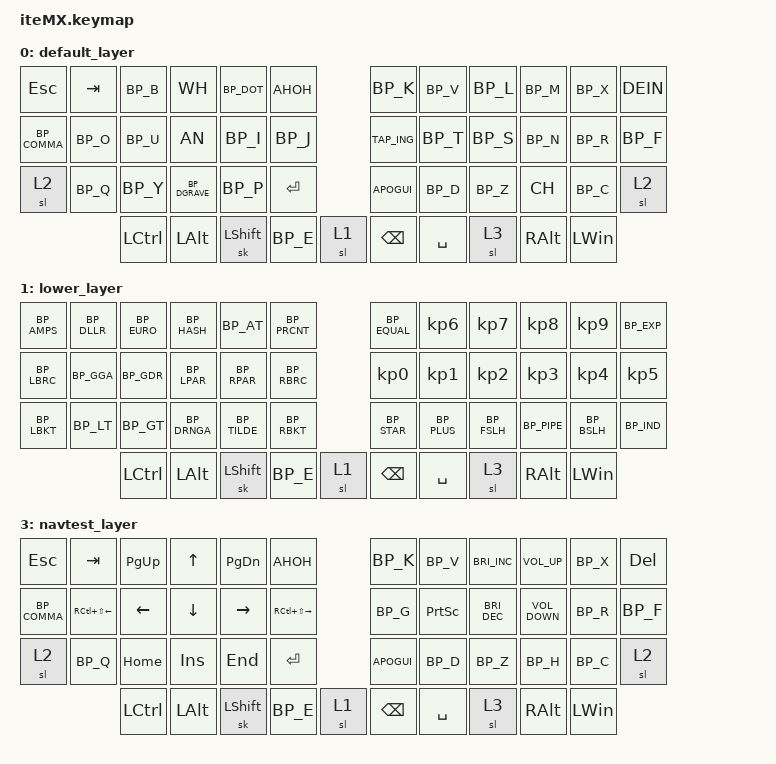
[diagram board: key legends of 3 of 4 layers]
#include <behaviors.dtsi>
#include "keys_bepo.h"
#include <dt-bindings/zmk/bt.h>
#include "mouse.dtsi"
#include <dt-bindings/zmk/outputs.h>
#include <dt-bindings/zmk/keys.h>

//shift circonflexe pour deux point sur le I1

#define default 0
#define lower 1
#define nav 2
#define navtest 3

&sk {
    release-after-ms = <1000>;
    quick-release;
    /delete-property/ ignore-modifiers;
};

/ {
    macros {
        MACRO_WH: WH {
            label = "WH";
            compatible = "zmk,behavior-macro";
            #binding-cells = <0>;
            bindings
                = <&macro_tap &kp BP_W &kp BP_H>
                ;
        };
        MACRO_MAJ_WH: MAJ_WH {
            label = "MAJ_WH";
            compatible = "zmk,behavior-macro";
            #binding-cells = <0>;
            bindings
            = <&macro_tap &kp LS(BP_W) &kp BP_H>
            ;
        };
        MACRO_ING: ING {
            label = "ING";
            compatible = "zmk,behavior-macro";
            #binding-cells = <0>;
            bindings
                = <&macro_tap &kp BP_I &kp BP_N &kp BP_G>
                ;
        };
        MACRO_CH: CH {
            label = "CH";
            compatible = "zmk,behavior-macro";
            #binding-cells = <0>;
            bindings
                = <&macro_tap &kp BP_C &kp BP_H>
                ;
        };
        MACRO_MAJ_CH: MAJ_CH {
            label = "MAJ_CH";
            compatible = "zmk,behavior-macro";
            #binding-cells = <0>;
            bindings
            = <&macro_tap &kp LS(BP_C) &kp BP_H>
            ;
        };
        MACRO_AN: AN {
            label = "AN";
            compatible = "zmk,behavior-macro";
            #binding-cells = <0>;
            bindings
                = <&macro_tap &kp BP_A &kp BP_N>
                ;
        };
        MACRO_MAJ_AN: MAJ_AN {
            label = "MAJ_AN";
            compatible = "zmk,behavior-macro";
            #binding-cells = <0>;
            bindings
            = <&macro_tap &kp LS(BP_A) &kp BP_N>
            ;
        };
    };
};

/ {
    behaviors {
        TAP_WH: tap_dance_0 {
            compatible = "zmk,behavior-tap-dance";
            label = "TAP_DANCE_0";
            #binding-cells = <0>;
            tapping-term-ms = <150>;
            bindings = <&kp BP_W>, <&MACRO_WH>;
        };
        TAP_MAJ_WH: tap_dance_1 {
            compatible = "zmk,behavior-tap-dance";
            label = "TAP_DANCE_1";
            #binding-cells = <0>;
            tapping-term-ms = <150>;
            bindings = <&kp BP_W>, <&MACRO_MAJ_WH>;
        };
        TAP_ING: tap_dance_2 {
            compatible = "zmk,behavior-tap-dance";
            label = "TAP_DANCE_2";
            #binding-cells = <0>;
            tapping-term-ms = <150>;
            bindings = <&kp BP_G>, <&MACRO_ING>;
        };
        TAP_CH: tap_dance_3 {
            compatible = "zmk,behavior-tap-dance";
            label = "TAP_DANCE_3";
            #binding-cells = <0>;
            tapping-term-ms = <150>;
            bindings = <&kp BP_H>, <&MACRO_CH>;
        };
        TAP_MAJ_CH: tap_dance_4 {
            compatible = "zmk,behavior-tap-dance";
            label = "TAP_DANCE_4";
            #binding-cells = <0>;
            tapping-term-ms = <150>;
            bindings = <&kp BP_H>, <&MACRO_MAJ_CH>;
        };
        TAP_AN: tap_dance_5 {
            compatible = "zmk,behavior-tap-dance";
            label = "TAP_DANCE_5";
            #binding-cells = <0>;
            tapping-term-ms = <150>;
            bindings = <&kp BP_A>, <&MACRO_AN>;
        };
        TAP_MAJ_AN: tap_dance_6 {
            compatible = "zmk,behavior-tap-dance";
            label = "TAP_DANCE_6";
            #binding-cells = <0>;
            tapping-term-ms = <150>;
            bindings = <&kp BP_A>, <&MACRO_MAJ_AN>;
        };
    };
};

/ {
    behaviors {
        AHOH: exclamation_question {
            compatible = "zmk,behavior-mod-morph";
            label = "EXCLAMATION_QUESTION";
            #binding-cells = <0>;
            bindings = <&kp BP_QMARK>, <&kp BP_EXCL>;
            mods = <(MOD_LSFT|MOD_RSFT)>;
        };
        APOGUI: apos_guillement {
            compatible = "zmk,behavior-mod-morph";
            label = "APOSTROPHE_GUILLEMET";
            #binding-cells = <0>;
            bindings = <&kp BP_APOS>, <&kp BP_DQT>;
            mods = <(MOD_LSFT|MOD_RSFT)>;
        };
        WH: WH_MAJ_MH {
            compatible = "zmk,behavior-mod-morph";
            label = "WH_MAJ_WH";
            #binding-cells = <0>;
            bindings = <&TAP_WH>, <&MACRO_MAJ_WH>;
            mods = <(MOD_LSFT|MOD_RSFT)>;
        };
        DEIN: DEL_INSERT {
            compatible = "zmk,behavior-mod-morph";
            label = "DEL_INSERT";
            #binding-cells = <0>;
            bindings = <&kp DEL>, <&kp INS>;
            mods = <(MOD_LSFT|MOD_RSFT)>;
        };
        CH: CH_MAJ_CH {
            compatible = "zmk,behavior-mod-morph";
            label = "CH_MAJ_CH";
            #binding-cells = <0>;
            bindings = <&TAP_CH>, <&MACRO_MAJ_CH>;
            mods = <(MOD_LSFT|MOD_RSFT)>;
        };
        AN: AN_MAJ_AN {
            compatible = "zmk,behavior-mod-morph";
            label = "AN_MAJ_AN";
            #binding-cells = <0>;
            bindings = <&TAP_AN>, <&MACRO_MAJ_AN>;
            mods = <(MOD_LSFT|MOD_RSFT)>;
        };
    };
};

#define COMBO(NAME, TIME, BINDINGS, KEYPOS) \
  combo_##NAME { \
    timeout-ms = <TIME>; \
    bindings = <BINDINGS>; \
    key-positions = <KEYPOS>; \
  };
//         ______________________                   ________________________
//        |0  |1  |2  |3  |4  |5  |                |6  |7  |8  |9  |10 |11 |
//        |12 |13 |14 |15 |16 |17 |                |18 |19 |20 |21 |22 |23 |
//        |24 |25 |26 |27 |28 |29 |___          ___|30 |31 |32 |33 |34 |35 |  
//             ‾‾‾|36 |37 |38 |39 |40 |        |41 |42 |43 |44 |45 |‾‾‾               
//                 ‾‾‾‾‾‾‾‾‾‾‾‾‾‾‾‾‾‾‾          ‾‾‾‾‾‾‾‾‾‾‾‾‾‾‾‾‾‾‾
/ {
        combos {
                compatible = "zmk,combos";

                COMBO(circonflexe, 70, &kp BP_CARET, 8 9)
                COMBO(tiret, 70, &kp BP_MINUS, 7 8)
                COMBO(underscore, 70, &kp BP_UNDER, 31 32)
                COMBO(accent_aigu, 70, &kp BP_DAIGU, 3 4)                
                COMBO(c_cedille, 70, &kp BP_CCED, 32 33 34)

                COMBO(supr, 50, &kp DEL, 4 16)
                COMBO(enter_un, 80, &kp ENTER, 13 14 15 16)
                COMBO(enter_two, 80, &kp ENTER, 14 15 16)
                COMBO(esc, 50, &kp ESC, 0 1)
                COMBO(caps_lock, 70, &kp CAPS, 38 43)

                COMBO(ctrl_z, 50, &kp LC(BP_Z), 27 28)
                COMBO(ctrl_c, 50, &kp LC(BP_C), 26 27)
                COMBO(ctrl_v, 50, &kp LC(BP_V), 28 29)
                COMBO(ctrl_x, 50, &kp LC(BP_X), 25 26)
                COMBO(ctrl_s, 70, &kp LC(BP_S), 4 5) 
                COMBO(shift_fdix, 70, &kp LS(F10), 7 19) 


//                COMBO(lower, 100, &mo 1, 40 42)

        };

    keymap {
        compatible = "zmk,keymap";

        default_layer {

            bindings = <
&kp ESC	        &kp TAB	      &kp BP_B    &WH          &kp BP_DOT     &AHOH                         &kp BP_K	    &kp BP_V	    &kp BP_L	&kp BP_M	&kp BP_X	&DEIN
&kp BP_COMMA	&kp BP_O	  &kp BP_U    &AN	        &kp BP_I	   &kp BP_J                 &TAP_ING        &kp BP_T	    &kp BP_S	&kp BP_N	&kp BP_R	&kp BP_F
&sl 2           &kp BP_Q	  &kp BP_Y    &kp BP_DGRAVE	    &kp BP_P	   &kp ENTER                &APOGUI 	    &kp BP_D	    &kp BP_Z    &CH    &kp BP_C	        &sl 2
                            &kp LCTRL    &kp LALT         &sk LSHFT      &kp BP_E	 &sl 1    &kp BSPC  &kp SPACE   &sl 3  &kp RALT	 &kp LWIN
            >;      
    };
    
    lower_layer {
		
        bindings = <
&kp BP_AMPS &kp BP_DLLR &kp BP_EURO	  &kp BP_HASH	&kp BP_AT 	    &kp BP_PRCNT	            &kp BP_EQUAL   &kp KP_N6    &kp KP_N7    &kp KP_N8    &kp KP_N9	 &kp BP_EXP
&kp BP_LBRC &kp BP_GGA	&kp BP_GDR	  &kp BP_LPAR	&kp BP_RPAR     &kp BP_RBRC                 &kp KP_N0       &kp KP_N1    &kp KP_N2    &kp KP_N3    &kp KP_N4	 &kp KP_N5
&kp BP_LBKT &kp BP_LT   &kp BP_GT     &kp BP_DRNGA  &kp BP_TILDE    &kp BP_RBKT                 &kp BP_STAR	   &kp BP_PLUS &kp BP_FSLH	&kp BP_PIPE	&kp BP_BSLH  &kp BP_IND
                        &kp LCTRL     &kp LALT      &sk LSHFT       &kp BP_E	 &sl 1    &kp BSPC  &kp SPACE   &sl 3  &kp RALT	 &kp LWIN
>;      
        };

    
        nav_layer {
    
                bindings = <
    &kp ESC	  &kp Z	          &mwh SCROLL_LEFT	         &mmv MOVE_UP	     &mwh SCROLL_RIGHT          &mwh SCROLL_UP              &kp F11	     &kp F6	    &kp F7   &kp F8	 &kp F9	 &kp F12
    &kp LEFT	&kp R	          &mmv MOVE_LEFT &mmv MOVE_DOWN    &mmv MOVE_RIGHT  &mwh SCROLL_DOWN                                &kp F10    &kp F1      &kp F2	&kp F3	 &kp F4	&kp F5
    &kp RC(LS(TAB))  &kp DLLR	&kp RC(LS(UP))    &kp RC(LS(DOWN))   &kp RC(LS(RIGHT))	      &kp RC(TAB)                   &kp N	     &kp I	    &kp B   &kp DOT  &kp H	&kp GRAVE
                              &trans       &trans         &mkp RCLK          &mkp LCLK	  &trans   &trans  &trans   &trans      &trans	           &trans           &trans
                >;      
            };
    
            navtest_layer {
    
                bindings = <
&kp ESC	        &kp TAB	               &kp PAGE_UP &kp UP     &kp PAGE_DOWN     &AHOH                       &kp BP_K	    &kp BP_V	    &kp C_BRIGHTNESS_INC	&kp C_VOLUME_UP	&kp BP_X	&kp DEL
&kp BP_COMMA	&kp RC(LS(LEFT))	   &kp LEFT     &kp DOWN    &kp RIGHT	   &kp RC(LS(RIGHT))             &kp BP_G       &kp PRINTSCREEN	    &kp C_BRIGHTNESS_DEC	&kp C_VOLUME_DOWN	&kp BP_R	&kp BP_F
&sl 2           &kp BP_Q	            &kp HOME     &kp INS     &kp END	   &kp ENTER                     &APOGUI 	    &kp BP_D	    &kp BP_Z    &kp BP_H    &kp BP_C	&sl 2
                                        &kp LCTRL   &kp LALT         &sk LSHFT      &kp BP_E	 &sl 1    &kp BSPC  &kp SPACE   &sl 3  &kp RALT	 &kp LWIN
                >;      
            };
    
        };
    };
